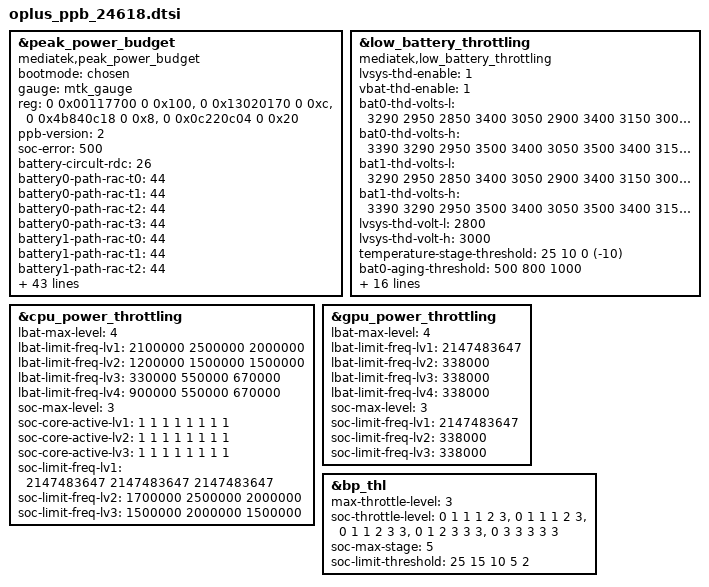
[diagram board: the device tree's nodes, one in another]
// SPDX-License-Identifier: GPL-2.0-only
/*
* Copyright (C) 2021-2020 Oplus. All rights reserved.
*/
#include <dt-bindings/iio/mt635x-auxadc.h>
#include <dt-bindings/pinctrl/mt6991-pinfunc.h>
#include <dt-bindings/pinctrl/mt65xx.h>

&peak_power_budget {
	compatible = "mediatek,peak_power_budget";
	bootmode = <&chosen>;
	gauge = <&mtk_gauge>;
	reg = <0 0x00117700 0 0x100>,
		<0 0x13020170 0 0xc>,
		<0 0x4b840c18 0 0x8>,
		<0 0x0c220c04 0 0x20>;
	reg-names = "ppb_sram",
		"hpt_ctrl","gpu_dbg", "cpu_dbg";

	ppb-version = <2>;
	soc-error = <500>;
	battery-circult-rdc  = <26>;
	battery0-path-rac-t0 = <44>;
	battery0-path-rac-t1 = <44>;
	battery0-path-rac-t2 = <44>;
	battery0-path-rac-t3 = <44>;
	battery1-path-rac-t0 = <44>;
	battery1-path-rac-t1 = <44>;
	battery1-path-rac-t2 = <44>;
	battery1-path-rac-t3 = <44>;
	battery2-path-rac-t0 = <44>;
	battery2-path-rac-t1 = <44>;
	battery2-path-rac-t2 = <44>;
	battery2-path-rac-t3 = <44>;
	temperature-threshold = <25 10 0>;
	system-ocp = <15000>;
	system-uvlo = <2400>;

	soc-max-level = <3>;     //+lv3
	soc-hpt-ctrl-lv1 = <7>;  //lv1 pre-uv on
	soc-hpt-ctrl-lv2 = <0>;  //lv2 pre-uv off
	soc-hpt-ctrl-lv3 = <0>;  //lv3 pre-uv off

	bat-ocv-table-num = <6>;
	bat0-ocv-table-t0-temperature = <50>;
	bat0-ocv-table-t0-qmax = <7208>;
	bat0-ocv-table-t0-size = <100>;
	bat0-ocv-table-t0 = <
			0       44618   0     100
			735     44484   0     100
			1471    44379   0     100
			2206    44288   0     100
			2941    44197   0     100
			3677    44111   0     100
			4412    44020   0     100
			5147    43924   0     100
			5883    43821   0     100
			6618    43728   0     100
			7354    43625   0     100
			8089    43514   0     100
			8824    43423   0     100
			9560    43308   0     100
			10295   43192   0     100
			11030   43081   0     100
			11766   42961   0     100
			12501   42841   0     100
			13236   42719   0     100
			13972   42583   0     100
			14707   42463   0     100
			15442   42338   0     100
			16178   42215   0     100
			16913   42083   0     100
			17648   41943   0     100
			18384   41818   0     100
			19119   41700   0     100
			19855   41575   0     100
			20590   41455   0     100
			21325   41298   0     100
			22061   41089   0     100
			22796   40867   0     100
			23531   40712   0     100
			24267   40579   0     100
			25002   40457   0     100
			25737   40347   0     100
			26473   40235   0     100
			27208   40134   0     100
			27943   40015   0     100
			28679   39931   0     100
			29414   39835   0     100
			30149   39742   0     100
			30885   39648   0     100
			31620   39556   0     100
			32356   39471   0     100
			33091   39384   0     100
			33826   39301   0     100
			34562   39218   0     100
			35297   39124   0     100
			36032   39020   0     100
			36768   38900   0     100
			37503   38786   0     100
			38238   38668   0     100
			38974   38558   0     100
			39709   38453   0     100
			40444   38349   0     100
			41180   38234   0     100
			41915   38109   0     100
			42651   37981   0     100
			43386   37861   0     100
			44121   37739   0     100
			44857   37617   0     100
			45592   37538   0     100
			46327   37469   0     100
			47063   37407   0     100
			47798   37335   0     100
			48533   37239   0     100
			49269   37082   0    100
			50004   36953   0    100
			50739   36827   0    100
			51475   36698   0    100
			52210   36568   0    100
			52945   36427   0    100
			53681   36287   0    100
			54416   36132   0    100
			55152   35973   0    100
			55887   35807   0    100
			56622   35637   0    100
			57358   35466   0    100
			58093   35303   0    100
			58828   35144   0    100
			59564   34984   0    100
			60299   34813   0    100
			61034   34645   0    100
			61770   34469   0    100
			62505   34272   0    100
			63240   34064   0    100
			63976   33837   0    100
			64711   33592   0    100
			65446   33344   0    100
			66182   33088   0    100
			66917   32836   0    100
			67653   32589   0    700
			68388   32339   0    700
			69123   32079   0    700
			69859   31752   0    700
			70594   31335   0    500
			71329   30735   0    500
			72065   29908   0    500
			72800   28918   0    500
		>;

		bat0-ocv-table-t1-temperature = <25>;
		bat0-ocv-table-t1-qmax = <7171>;
		bat0-ocv-table-t1-size = <100>;
		bat0-ocv-table-t1 = <
			0       44618   0     100
			735     44484   0     100
			1471    44379   0     100
			2206    44288   0     100
			2941    44197   0     100
			3677    44111   0     100
			4412    44020   0     100
			5147    43924   0     100
			5883    43821   0     100
			6618    43728   0     100
			7354    43625   0     100
			8089    43514   0     100
			8824    43423   0     100
			9560    43308   0     100
			10295   43192   0     100
			11030   43081   0     100
			11766   42961   0     100
			12501   42841   0     100
			13236   42719   0     100
			13972   42583   0     100
			14707   42463   0     100
			15442   42338   0     100
			16178   42215   0     100
			16913   42083   0     100
			17648   41943   0     100
			18384   41818   0     100
			19119   41700   0     100
			19855   41575   0     100
			20590   41455   0     100
			21325   41298   0     100
			22061   41089   0     100
			22796   40867   0     100
			23531   40712   0     100
			24267   40579   0     100
			25002   40457   0     100
			25737   40347   0     100
			26473   40235   0     100
			27208   40134   0     100
			27943   40015   0     100
			28679   39931   0     100
			29414   39835   0     100
			30149   39742   0     100
			30885   39648   0     100
			31620   39556   0     100
			32356   39471   0     100
			33091   39384   0     100
			33826   39301   0     100
			34562   39218   0     100
			35297   39124   0     100
			36032   39020   0     100
			36768   38900   0     100
			37503   38786   0     100
			38238   38668   0     100
			38974   38558   0     100
			39709   38453   0     100
			40444   38349   0     100
			41180   38234   0     100
			41915   38109   0     100
			42651   37981   0     100
			43386   37861   0     100
			44121   37739   0     100
			44857   37617   0     100
			45592   37538   0     100
			46327   37469   0     100
			47063   37407   0     100
			47798   37335   0     100
			48533   37239   0     100
			49269   37082   0    100
			50004   36953   0    100
			50739   36827   0    100
			51475   36698   0    100
			52210   36568   0    100
			52945   36427   0    100
			53681   36287   0    100
			54416   36132   0    100
			55152   35973   0    100
			55887   35807   0    100
			56622   35637   0    100
			57358   35466   0    100
			58093   35303   0    100
			58828   35144   0    100
			59564   34984   0    100
			60299   34813   0    100
			61034   34645   0    100
			61770   34469   0    100
			62505   34272   0    100
			63240   34064   0    100
			63976   33837   0    100
			64711   33592   0    100
			65446   33344   0    100
			66182   33088   0    100
			66917   32836   0    100
			67653   32589   0    700
			68388   32339   0    700
			69123   32079   0    700
			69859   31752   0    700
			70594   31335   0    500
			71329   30735   0    500
			72065   29908   0    500
			72800   28918   0    500
		    >;

		bat0-ocv-table-t2-temperature = <10>;
		bat0-ocv-table-t2-qmax = <7202>;
		bat0-ocv-table-t2-size = <100>;
		bat0-ocv-table-t2 = <
			0       44618   0     100
			735     44484   0     100
			1471    44379   0     100
			2206    44288   0     100
			2941    44197   0     100
			3677    44111   0     100
			4412    44020   0     100
			5147    43924   0     100
			5883    43821   0     100
			6618    43728   0     100
			7354    43625   0     100
			8089    43514   0     100
			8824    43423   0     100
			9560    43308   0     100
			10295   43192   0     100
			11030   43081   0     100
			11766   42961   0     100
			12501   42841   0     100
			13236   42719   0     100
			13972   42583   0     100
			14707   42463   0     100
			15442   42338   0     100
			16178   42215   0     100
			16913   42083   0     100
			17648   41943   0     100
			18384   41818   0     100
			19119   41700   0     100
			19855   41575   0     100
			20590   41455   0     100
			21325   41298   0     100
			22061   41089   0     100
			22796   40867   0     100
			23531   40712   0     100
			24267   40579   0     100
			25002   40457   0     100
			25737   40347   0     100
			26473   40235   0     100
			27208   40134   0     100
			27943   40015   0     100
			28679   39931   0     100
			29414   39835   0     100
			30149   39742   0     100
			30885   39648   0     100
			31620   39556   0     100
			32356   39471   0     100
			33091   39384   0     100
			33826   39301   0     100
			34562   39218   0     100
			35297   39124   0     100
			36032   39020   0     100
			36768   38900   0     100
			37503   38786   0     100
			38238   38668   0     100
			38974   38558   0     100
			39709   38453   0     100
			40444   38349   0     100
			41180   38234   0     100
			41915   38109   0     100
			42651   37981   0     100
			43386   37861   0     100
			44121   37739   0     100
			44857   37617   0     100
			45592   37538   0     100
			46327   37469   0     100
			47063   37407   0     100
			47798   37335   0     100
			48533   37239   0     100
			49269   37082   0    100
			50004   36953   0    100
			50739   36827   0    100
			51475   36698   0    100
			52210   36568   0    100
			52945   36427   0    100
			53681   36287   0    100
			54416   36132   0    100
			55152   35973   0    100
			55887   35807   0    100
			56622   35637   0    100
			57358   35466   0    100
			58093   35303   0    100
			58828   35144   0    100
			59564   34984   0    100
			60299   34813   0    100
			61034   34645   0    100
			61770   34469   0    100
			62505   34272   0    100
			63240   34064   0    100
			63976   33837   0    100
			64711   33592   0    100
			65446   33344   0    100
			66182   33088   0    400
			66917   32836   0    400
			67653   32589   0    700
			68388   32339   0    700
			69123   32079   0    700
			69859   31752   0    700
			70594   31335   0    800
			71329   30735   0    800
			72065   29908   0    800
			72800   28918   0    800
			>;

		bat0-ocv-table-t3-temperature = <0>;
		bat0-ocv-table-t3-qmax = <6806>;
		bat0-ocv-table-t3-size = <100>;
		bat0-ocv-table-t3 = <
			0       44618   0     100
			735     44484   0     100
			1471    44379   0     100
			2206    44288   0     100
			2941    44197   0     100
			3677    44111   0     100
			4412    44020   0     100
			5147    43924   0     100
			5883    43821   0     100
			6618    43728   0     100
			7354    43625   0     100
			8089    43514   0     100
			8824    43423   0     100
			9560    43308   0     100
			10295   43192   0     100
			11030   43081   0     100
			11766   42961   0     100
			12501   42841   0     100
			13236   42719   0     100
			13972   42583   0     100
			14707   42463   0     100
			15442   42338   0     100
			16178   42215   0     100
			16913   42083   0     100
			17648   41943   0     100
			18384   41818   0     100
			19119   41700   0     100
			19855   41575   0     100
			20590   41455   0     100
			21325   41298   0     100
			22061   41089   0     100
			22796   40867   0     100
			23531   40712   0     100
			24267   40579   0     100
			25002   40457   0     100
			25737   40347   0     100
			26473   40235   0     100
			27208   40134   0     100
			27943   40015   0     100
			28679   39931   0     100
			29414   39835   0     100
			30149   39742   0     100
			30885   39648   0     100
			31620   39556   0     100
			32356   39471   0     100
			33091   39384   0     100
			33826   39301   0     100
			34562   39218   0     100
			35297   39124   0     100
			36032   39020   0     100
			36768   38900   0     100
			37503   38786   0     100
			38238   38668   0     100
			38974   38558   0     100
			39709   38453   0     100
			40444   38349   0     100
			41180   38234   0     100
			41915   38109   0     100
			42651   37981   0     100
			43386   37861   0     100
			44121   37739   0     100
			44857   37617   0     100
			45592   37538   0     100
			46327   37469   0     100
			47063   37407   0     100
			47798   37335   0     100
			48533   37239   0     100
			49269   37082   0    100
			50004   36953   0    100
			50739   36827   0    100
			51475   36698   0    100
			52210   36568   0    100
			52945   36427   0    100
			53681   36287   0    100
			54416   36132   0    100
			55152   35973   0    100
			55887   35807   0    100
			56622   35637   0    100
			57358   35466   0    100
			58093   35303   0    100
			58828   35144   0    100
			59564   34984   0    100
			60299   34813   0    100
			61034   34645   0    100
			61770   34469   0    100
			62505   34272   0    1000
			63240   34064   0    1000
			63976   33837   0    1000
			64711   33592   0    1000
			65446   33344   0    1000
			66182   33088   0    1000
			66917   32836   0    1000
			67653   32589   0    700
			68388   32339   0    700
			69123   32079   0    700
			69859   31752   0    700
			70594   31335   0    800
			71329   30735   0    800
			72065   29908   0    800
			72800   28918   0    800
		>;

		bat0-ocv-table-t4-temperature = <(-10)>;
		bat0-ocv-table-t4-qmax = <6359>;
		bat0-ocv-table-t4-size = <100>;
		bat0-ocv-table-t4 = <
			0       44618   0     100
			735     44484   0     100
			1471    44379   0     100
			2206    44288   0     100
			2941    44197   0     100
			3677    44111   0     100
			4412    44020   0     100
			5147    43924   0     100
			5883    43821   0     100
			6618    43728   0     100
			7354    43625   0     100
			8089    43514   0     100
			8824    43423   0     100
			9560    43308   0     100
			10295   43192   0     100
			11030   43081   0     100
			11766   42961   0     100
			12501   42841   0     100
			13236   42719   0     100
			13972   42583   0     100
			14707   42463   0     100
			15442   42338   0     100
			16178   42215   0     100
			16913   42083   0     100
			17648   41943   0     100
			18384   41818   0     100
			19119   41700   0     100
			19855   41575   0     100
			20590   41455   0     100
			21325   41298   0     100
			22061   41089   0     100
			22796   40867   0     100
			23531   40712   0     100
			24267   40579   0     100
			25002   40457   0     100
			25737   40347   0     100
			26473   40235   0     100
			27208   40134   0     100
			27943   40015   0     100
			28679   39931   0     100
			29414   39835   0     100
			30149   39742   0     100
			30885   39648   0     100
			31620   39556   0     100
			32356   39471   0     100
			33091   39384   0     100
			33826   39301   0     100
			34562   39218   0     100
			35297   39124   0     100
			36032   39020   0     100
			36768   38900   0     100
			37503   38786   0     100
			38238   38668   0     100
			38974   38558   0     100
			39709   38453   0     100
			40444   38349   0     100
			41180   38234   0     100
			41915   38109   0     100
			42651   37981   0     100
			43386   37861   0     100
			44121   37739   0     1000
			44857   37617   0     1000
			45592   37538   0     1000
			46327   37469   0     1000
			47063   37407   0     1000
			47798   37335   0     1000
			48533   37239   0     1000
			49269   37082   0    1000
			50004   36953   0    1000
			50739   36827   0    1000
			51475   36698   0    1000
			52210   36568   0    1000
			52945   36427   0    1000
			53681   36287   0    1000
			54416   36132   0    1000
			55152   35973   0    1000
			55887   35807   0    1000
			56622   35637   0    1000
			57358   35466   0    1000
			58093   35303   0    1000
			58828   35144   0    1000
			59564   34984   0    1000
			60299   34813   0    1000
			61034   34645   0    1000
			61770   34469   0    1000
			62505   34272   0    1000
			63240   34064   0    1000
			63976   33837   0    1000
			64711   33592   0    1000
			65446   33344   0    1000
			66182   33088   0    1000
			66917   32836   0    1000
			67653   32589   0    1000
			68388   32339   0    1000
			69123   32079   0    1000
			69859   31752   0    1000
			70594   31335   0    1000
			71329   30735   0    1000
			72065   29908   0    1000
			72800   28918   0    1000
		>;

		bat0-ocv-table-t5-temperature = <(-20)>;
		bat0-ocv-table-t5-qmax = <5815>;
		bat0-ocv-table-t5-size = <100>;
		bat0-ocv-table-t5 = <
			0       44618   0    751
			735     44484   0    751
			1471    44379   0    732
			2206    44288   0    736
			2941    44197   0    713
			3677    44111   0    731
			4412    44020   0    736
			5147    43924   0    724
			5883    43821   0    706
			6618    43728   0    713
			7354    43625   0     727
			8089    43514   0     686
			8824    43423   0     749
			9560    43308   0     748
			10295   43192   0     736
			11030   43081   0     744
			11766   42961   0     742
			12501   42841   0     756
			13236   42719   0     762
			13972   42583   0     752
			14707   42463   0     762
			15442   42338   0     765
			16178   42215   0     773
			16913   42083   0     773
			17648   41943   0     783
			18384   41818   0     796
			19119   41700   0     816
			19855   41575   0     833
			20590   41455   0     862
			21325   41298   0     848
			22061   41089   0     1000
			22796   40867   0     1000
			23531   40712   0     1000
			24267   40579   0     1000
			25002   40457   0     1000
			25737   40347   0     1000
			26473   40235   0     1000
			27208   40134   0     1000
			27943   40015   0     1000
			28679   39931   0     1000
			29414   39835   0     1000
			30149   39742   0     1000
			30885   39648   0     1000
			31620   39556   0     1000
			32356   39471   0     1000
			33091   39384   0     1000
			33826   39301   0     1000
			34562   39218   0     1000
			35297   39124   0     1000
			36032   39020   0     1000
			36768   38900   0     1000
			37503   38786   0     1000
			38238   38668   0     1000
			38974   38558   0     1000
			39709   38453   0     1000
			40444   38349   0     1000
			41180   38234   0     1000
			41915   38109   0     1000
			42651   37981   0     1000
			43386   37861   0     1000
			44121   37739   0     1000
			44857   37617   0     1000
			45592   37538   0     1000
			46327   37469   0     1000
			47063   37407   0     1000
			47798   37335   0     1000
			48533   37239   0     1000
			49269   37082   0    1000
			50004   36953   0    1000
			50739   36827   0    1000
			51475   36698   0    1000
			52210   36568   0    1000
			52945   36427   0    1000
			53681   36287   0    1000
			54416   36132   0    1000
			55152   35973   0    1000
			55887   35807   0    1000
			56622   35637   0    1000
			57358   35466   0    1000
			58093   35303   0    1000
			58828   35144   0    1000
			59564   34984   0    1000
			60299   34813   0    1000
			61034   34645   0    1000
			61770   34469   0    1000
			62505   34272   0    1000
			63240   34064   0    1000
			63976   33837   0    1000
			64711   33592   0    1000
			65446   33344   0    1000
			66182   33088   0    1000
			66917   32836   0    1000
			67653   32589   0    1000
			68388   32339   0    1000
			69123   32079   0    1000
			69859   31752   0    1000
			70594   31335   0    1000
			71329   30735   0    1000
			72065   29908   0    1000
			72800   28918   0    1000
			>;
	};

&low_battery_throttling {
		compatible = "mediatek,low_battery_throttling";
		lvsys-thd-enable = <1>;
		vbat-thd-enable = <1>;
		bat0-thd-volts-l = <
			3290 2950 2850    //PT threshhold down
			3400 3050 2900
			3400 3150 3000
			3710 3350 3200
			3800 3560 3350>;
		bat0-thd-volts-h = <
			3390 3290 2950
			3500 3400 3050
			3500 3400 3150
			3810 3710 3350
			3900 3800 3560>;
		bat1-thd-volts-l = <
			3290 2950 2850    //PT threshhold down
			3400 3050 2900
			3400 3150 3000
			3710 3350 3200
			3800 3560 3350>;
		bat1-thd-volts-h = <
			3390 3290 2950
			3500 3400 3050
			3500 3400 3150
			3810 3710 3350
			3900 3800 3560>;
		lvsys-thd-volt-l = <2800>;   //0.1V down
		lvsys-thd-volt-h = <3000>;   //0.1V down

		temperature-stage-threshold = <25 10 0 (-10)>;
		bat0-aging-threshold = <500 800 1000>;
		bat0-aging-volts-t0 =  <50 100 150>;
		bat0-aging-volts-t1 =  <50 100 150>;
		bat0-aging-volts-t2 =  <50 100 150>;
		bat0-aging-volts-t3 =  <50 100 150>;
		bat0-aging-volts-t4 =  <50 100 150>;
		bat1-aging-threshold = <500 800 1000>;
		bat1-aging-volts-t0 =  <0 0>;
		bat1-aging-volts-t1 =  <0 0>;
		bat1-aging-volts-t2 =  <0 0>;
		bat1-aging-volts-t3 =  <0 0>;
		bat1-aging-volts-t4 =  <0 0>;
		pt-shutdown-enable = <0>;
		throttle-level =  <0 1 2 3>,
				  <0 1 2 3>,
				  <0 1 2 3>,
				  <0 2 4 3>,
				  <0 2 4 3>;
		bootmode = <&chosen>;
		gauge = <&mtk_gauge>;
};

&cpu_power_throttling {
	lbat-max-level = <4>;
	lbat-limit-freq-lv1 = < 2100000  2500000 2000000>;
	lbat-limit-freq-lv2 = < 1200000  1500000 1500000>;
	lbat-limit-freq-lv3 = < 330000   550000 670000>;
	lbat-limit-freq-lv4 = < 900000   550000 670000>;

	soc-max-level = <3>;
	soc-core-active-lv1 = < 1 1 1 1 1 1 1 1 >;
	soc-core-active-lv2 = < 1 1 1 1 1 1 1 1 >;
	soc-core-active-lv3 = < 1 1 1 1 1 1 1 1 >;

	soc-limit-freq-lv1 = < 2147483647  2147483647 2147483647 >;
	soc-limit-freq-lv2 = < 1700000 2500000 2000000>;
	soc-limit-freq-lv3 = < 1500000 2000000 1500000>;
};

&gpu_power_throttling {
	lbat-max-level = <4>;
	lbat-limit-freq-lv1 = <2147483647>;
	lbat-limit-freq-lv2 = <338000>;
	lbat-limit-freq-lv3 = <338000>;
	lbat-limit-freq-lv4 = <338000>;

	soc-max-level = <3>;
	soc-limit-freq-lv1 = <2147483647>;
	soc-limit-freq-lv2 = <338000>;
	soc-limit-freq-lv3 = <338000>;
};

&bp_thl {
	max-throttle-level = <3>;   //+lv3
	soc-throttle-level =
		<0 1 1 1 2 3>, //temperature stage 0
		<0 1 1 1 2 3>, //temperature stage 1
		<0 1 1 2 3 3>, //temperature stage 2
		<0 1 2 3 3 3>,//temperature stage 3
                <0 3 3 3 3 3>;//temperature stage 4
	soc-max-stage = <5>;
	soc-limit-threshold = <25 15 10 5 2>;
};
